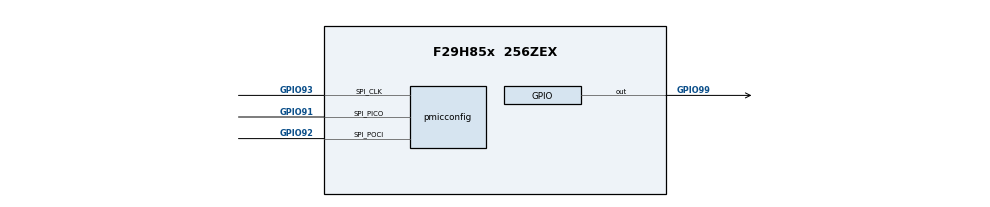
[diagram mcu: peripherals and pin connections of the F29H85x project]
/**
 * @cliArgs --device "F29H85x" --package "256ZEX" --part "F29H85x_256ZEX" --context "CPU1" --product "MCU_SDK_F29H85x@1.02.02.00"
 * @versions {"tool":"1.25.0+4237"}
 */

    
const divider15       = system.clockTree["PLL_REFDIV"];
divider15.divideValue = 1;

const multiplier1         = system.clockTree["PLL_IMULT"];
multiplier1.multiplyValue = 40;

const mux7       = system.clockTree["OSCCLKSRCSEL"];
mux7.inputSelect = "INTOSC2";

/**
 * Import the modules used in this configuration.
 */
const jtag          = scripting.addModule("/driverlib/jtag.js");
const pmicconfig    = scripting.addModule("/driverlib/pmicconfig.js");
const clock_c29_sdk = scripting.addModule("/kernel/dpl/clock_c29_sdk");

pmicconfig.pmicspi.spi.$assign             = "SPID";
pmicconfig.pmicspi.spi.spi_picoPin.$assign = "GPIO91";
pmicconfig.pmicspi.spi.spi_pociPin.$assign = "GPIO92";
pmicconfig.pmicspi.spi.spi_clkPin.$assign  = "GPIO93";
pmicconfig.pmicspi.picoQual.$name          = "myGPIOQUAL0";
pmicconfig.pmicspi.pociQual.$name          = "myGPIOQUAL1";
pmicconfig.pmicspi.clkQual.$name           = "myGPIOQUAL2";
pmicconfig.pmicspi.periphClock.$name       = "driverlib_perClock1";
pmicconfig.pmicspi.periphConfig.$name      = "driverlib_perConfig0";
pmicconfig.cspin.gpioPin.$assign           = "GPIO99";

clock_c29_sdk.dplTimer.periphClock.$name                  = "driverlib_perClock0";
clock_c29_sdk.dplTimer.periphClock.pinmuxPeripheralModule = scripting.forceWrite("");

/**
 * Pinmux solution for unlocked pins/peripherals. This ensures that minor changes to the automatic solver in a future
 * version of the tool will not impact the pinmux you originally saw.  These lines can be completely deleted in order to
 * re-solve from scratch.
 */
jtag.JTAG.$suggestSolution                         = "JTAG";
jtag.JTAG.tdoPin.$suggestSolution                  = "GPIO223/TDO";
jtag.JTAG.tdiPin.$suggestSolution                  = "GPIO222/TDI";
